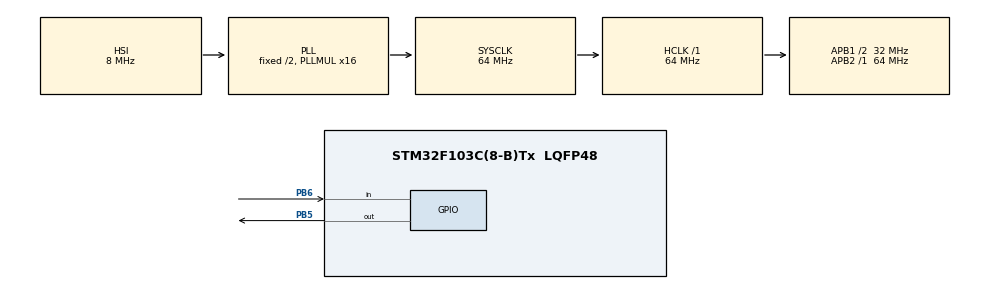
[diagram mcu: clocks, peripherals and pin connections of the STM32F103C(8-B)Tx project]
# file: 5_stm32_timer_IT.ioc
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Mcu.Family=STM32F1
Mcu.Name=STM32F103C(8-B)Tx
Mcu.Package=LQFP48
NVIC.PriorityGroup=NVIC_PRIORITYGROUP_4
PA13.Mode=Serial_Wire
PA13.Signal=SYS_JTMS-SWDIO
PA14.Mode=Serial_Wire
PA14.Signal=SYS_JTCK-SWCLK
PB5.GPIO_PuPd=GPIO_PULLUP
PB5.Signal=GPIO_Output
PB6.Signal=GPIO_Input
ProjectManager.HeapSize=0x200
ProjectManager.StackSize=0x400
ProjectManager.TargetToolchain=MDK-ARM V5.32
RCC.AHBFreq_Value=64000000
RCC.APB1CLKDivider=RCC_HCLK_DIV2
RCC.APB1Freq_Value=32000000
RCC.APB1TimFreq_Value=64000000
RCC.APB2Freq_Value=64000000
RCC.APB2TimFreq_Value=64000000
RCC.HCLKFreq_Value=64000000
RCC.PLLMUL=RCC_PLL_MUL16
RCC.SYSCLKFreq_VALUE=64000000
RCC.SYSCLKSource=RCC_SYSCLKSOURCE_PLLCLK
RCC.USBFreq_Value=64000000
TIM2.Prescaler=63
VP_TIM2_VS_ClockSourceINT.Mode=Internal
board=custom

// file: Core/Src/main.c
/* USER CODE BEGIN Header */
/**
  ******************************************************************************
  * @file           : main.c
  * @brief          : Main program body
  ******************************************************************************
  * @attention
  *
  * Copyright (c) 2026 STMicroelectronics.
  * All rights reserved.
  *
  * This software is licensed under terms that can be found in the LICENSE file
  * in the root directory of this software component.
  * If no LICENSE file comes with this software, it is provided AS-IS.
  *
  ******************************************************************************
  */
/* USER CODE END Header */
#include "main.h"

TIM_HandleTypeDef htim2;

void SystemClock_Config(void);
static void MX_GPIO_Init(void);
static void MX_TIM2_Init(void);

/* USER CODE BEGIN 0 */

void my_delay_us(uint16_t us);
void setPinToGPIO_output(GPIO_TypeDef *port, uint16_t pin);

void my_delay_us(uint16_t us) {
	HAL_TIM_Base_Start(&htim2);

	htim2.Instance->CNT = 0;
	while(htim2.Instance->CNT < us) {
		// waiting
	}

	HAL_TIM_Base_Stop(&htim2);
}

void setPinToGPIO_output(GPIO_TypeDef *port, uint16_t pin) {
	GPIO_InitTypeDef GPIO_InitStruct = {0};

	/*Configure GPIO pin*/
  GPIO_InitStruct.Pin = pin;
  GPIO_InitStruct.Mode = GPIO_MODE_OUTPUT_PP;
  GPIO_InitStruct.Pull = GPIO_PULLUP;
  GPIO_InitStruct.Speed = GPIO_SPEED_FREQ_LOW;
  HAL_GPIO_Init(port, &GPIO_InitStruct);
}

void setPinToGPIO_input(GPIO_TypeDef *port, uint16_t pin) {
	GPIO_InitTypeDef GPIO_InitStruct = {0};

	/*Configure GPIO pin*/
  GPIO_InitStruct.Pin = pin;
  GPIO_InitStruct.Mode = GPIO_MODE_INPUT;
  GPIO_InitStruct.Pull = GPIO_PULLUP;
  HAL_GPIO_Init(port, &GPIO_InitStruct);
}

void DHT11_Start() {
  setPinToGPIO_output(GPIOB, GPIO_PIN_5);

  HAL_GPIO_WritePin(GPIOB, GPIO_PIN_5, 1);
  HAL_GPIO_WritePin(GPIOB, GPIO_PIN_5, 0); HAL_Delay(20);
	HAL_GPIO_WritePin(GPIOB, GPIO_PIN_5, 1);

  setPinToGPIO_input(GPIOB, GPIO_PIN_5);

  // ============================
  // chua co thuat toan check loi
  // ============================

  while(HAL_GPIO_ReadPin(GPIOB, GPIO_PIN_5) == 1) { } // doi = 0
  while(HAL_GPIO_ReadPin(GPIOB, GPIO_PIN_5) == 0) { } // doi = 1
  while(HAL_GPIO_ReadPin(GPIOB, GPIO_PIN_5) == 1) { } // doi = 0

  // ============================
  // 5bytes (40bits bat dau duoc truyen)
  // ============================

}

uint8_t DHT11_Read_byte() {
  uint8_t res = 0;

  for(int i = 0; i < 8; ++i) {
    while(HAL_GPIO_ReadPin(GPIOB, GPIO_PIN_5) == 0) {};
    my_delay_us(50);
    if(HAL_GPIO_ReadPin(GPIOB, GPIO_PIN_5) == 1) {
      // bit 1
      res = (res << 1) | (1 << 0);
			while(HAL_GPIO_ReadPin(GPIOB, GPIO_PIN_5) == 1) {};
    } else {
      // bit 0
      res = (res << 1) & ~(1 << 0);
    }
  }

  return res;
}

  uint8_t int_Tem = 0
          , int_Hum = 0
          , float_Tem = 0
          , float_Hum = 0
          , checkSum = 0;

void DHT11_Handler() {
  DHT11_Start();

  // Data format:
  //          8bit integral RH data
  //        + 8bit decimal RH data
  //        + 8bit integral T data
  //        + 8bit decimal T data
  //        + 8bit check sum.

  int_Hum   = DHT11_Read_byte();
  float_Hum = DHT11_Read_byte();
  int_Tem   = DHT11_Read_byte();
  float_Tem = DHT11_Read_byte();
  checkSum  = DHT11_Read_byte();

}

/* USER CODE END 0 */

int main(void)
{

  /* MCU Configuration--------------------------------------------------------*/

  /* Reset of all peripherals, Initializes the Flash interface and the Systick. */
  HAL_Init();

  /* Configure the system clock */
  SystemClock_Config();

  /* Initialize all configured peripherals */
  MX_GPIO_Init();
  MX_TIM2_Init();

  /* Infinite loop */
  while (1)
  {
		DHT11_Handler();
		HAL_Delay(1000);
  }
}

void SystemClock_Config(void)
{
  RCC_OscInitTypeDef RCC_OscInitStruct = {0};
  RCC_ClkInitTypeDef RCC_ClkInitStruct = {0};

  /** Initializes the RCC Oscillators according to the specified parameters
  * in the RCC_OscInitTypeDef structure.
  */
  RCC_OscInitStruct.OscillatorType = RCC_OSCILLATORTYPE_HSI;
  RCC_OscInitStruct.HSIState = RCC_HSI_ON;
  RCC_OscInitStruct.HSICalibrationValue = RCC_HSICALIBRATION_DEFAULT;
  RCC_OscInitStruct.PLL.PLLState = RCC_PLL_ON;
  RCC_OscInitStruct.PLL.PLLSource = RCC_PLLSOURCE_HSI_DIV2;
  RCC_OscInitStruct.PLL.PLLMUL = RCC_PLL_MUL16;
  if (HAL_RCC_OscConfig(&RCC_OscInitStruct) != HAL_OK)
  {
    Error_Handler();
  }

  /** Initializes the CPU, AHB and APB buses clocks
  */
  RCC_ClkInitStruct.ClockType = RCC_CLOCKTYPE_HCLK|RCC_CLOCKTYPE_SYSCLK
                              |RCC_CLOCKTYPE_PCLK1|RCC_CLOCKTYPE_PCLK2;
  RCC_ClkInitStruct.SYSCLKSource = RCC_SYSCLKSOURCE_PLLCLK;
  RCC_ClkInitStruct.AHBCLKDivider = RCC_SYSCLK_DIV1;
  RCC_ClkInitStruct.APB1CLKDivider = RCC_HCLK_DIV2;
  RCC_ClkInitStruct.APB2CLKDivider = RCC_HCLK_DIV1;

  if (HAL_RCC_ClockConfig(&RCC_ClkInitStruct, FLASH_LATENCY_2) != HAL_OK)
  {
    Error_Handler();
  }
}

static void MX_TIM2_Init(void)
{

  TIM_ClockConfigTypeDef sClockSourceConfig = {0};
  TIM_MasterConfigTypeDef sMasterConfig = {0};

  htim2.Instance = TIM2;
  htim2.Init.Prescaler = 63;
  htim2.Init.CounterMode = TIM_COUNTERMODE_UP;
  htim2.Init.Period = 63999;
  htim2.Init.ClockDivision = TIM_CLOCKDIVISION_DIV1;
  htim2.Init.AutoReloadPreload = TIM_AUTORELOAD_PRELOAD_DISABLE;
  if (HAL_TIM_Base_Init(&htim2) != HAL_OK)
  {
    Error_Handler();
  }
  sClockSourceConfig.ClockSource = TIM_CLOCKSOURCE_INTERNAL;
  if (HAL_TIM_ConfigClockSource(&htim2, &sClockSourceConfig) != HAL_OK)
  {
    Error_Handler();
  }
  sMasterConfig.MasterOutputTrigger = TIM_TRGO_RESET;
  sMasterConfig.MasterSlaveMode = TIM_MASTERSLAVEMODE_DISABLE;
  if (HAL_TIMEx_MasterConfigSynchronization(&htim2, &sMasterConfig) != HAL_OK)
  {
    Error_Handler();
  }

}

static void MX_GPIO_Init(void)
{
  GPIO_InitTypeDef GPIO_InitStruct = {0};

  /* GPIO Ports Clock Enable */
  __HAL_RCC_GPIOA_CLK_ENABLE();
  __HAL_RCC_GPIOB_CLK_ENABLE();

  /*Configure GPIO pin Output Level */
  HAL_GPIO_WritePin(GPIOB, GPIO_PIN_5, GPIO_PIN_RESET);

  /*Configure GPIO pin : PB5 */
  GPIO_InitStruct.Pin = GPIO_PIN_5;
  GPIO_InitStruct.Mode = GPIO_MODE_OUTPUT_PP;
  GPIO_InitStruct.Pull = GPIO_PULLUP;
  GPIO_InitStruct.Speed = GPIO_SPEED_FREQ_LOW;
  HAL_GPIO_Init(GPIOB, &GPIO_InitStruct);

  /*Configure GPIO pin : PB6 */
  GPIO_InitStruct.Pin = GPIO_PIN_6;
  GPIO_InitStruct.Mode = GPIO_MODE_INPUT;
  GPIO_InitStruct.Pull = GPIO_NOPULL;
  HAL_GPIO_Init(GPIOB, &GPIO_InitStruct);

}

void Error_Handler(void)
{
  __disable_irq();
  while (1)
  {
  }
}
